VERSION ""

NS_ :

BS_:

BU_:
VAL_TABLE_ ETC_subModes 4 "Position Control" 3 "PWM Control" 2 "Calibration" 1 "Normal" 0 "Disabled" ;
VAL_TABLE_ ETC_modes 3 "Diagnostic" 2 "Run" 1 "Standby" 0 "ESTOP" ;
VAL_TABLE_ motorControlModes 2 "Position" 1 "PWM" 0 "Off" ;
VAL_TABLE_ throttlePosInputModes 2 "VectorBox" 1 "CCP" 0 "Disabled" ;

BO_ 3221225472 VECTOR__INDEPENDENT_SIG_MSG: 0 Vector__XXX
 SG_ ETC_motorDriverEnabled_Raw : 0|8@1+ (1,0) [0|255] "bool" Vector__XXX
 SG_ ETC_motorBPWM_Raw : 0|8@1+ (1,0) [0|255] "%" Vector__XXX
 SG_ ETC_motorAPWM_Raw : 0|8@1+ (1,0) [0|255] "%" Vector__XXX

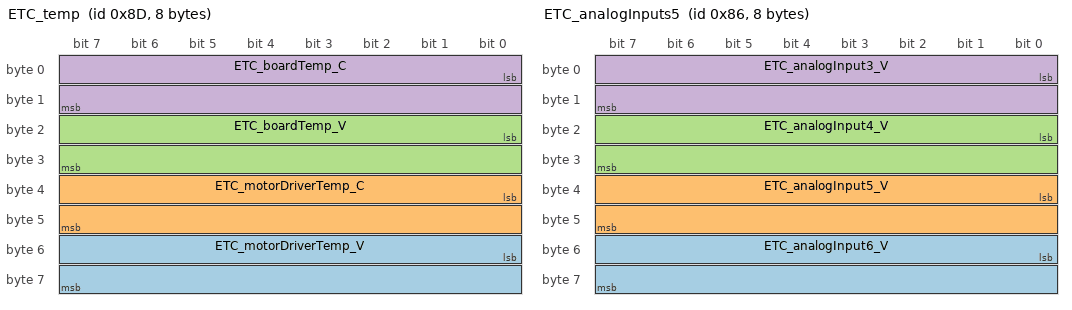
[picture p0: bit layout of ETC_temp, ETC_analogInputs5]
BO_ 141 ETC_temp: 8 Vector__XXX
 SG_ ETC_motorDriverTemp_V : 48|16@1+ (0.01,0) [0|655.35] "" Vector__XXX
 SG_ ETC_motorDriverTemp_C : 32|16@1- (0.01,0) [-327.68|327.67] "" Vector__XXX
 SG_ ETC_boardTemp_V : 16|16@1+ (0.01,0) [0|655.35] "" Vector__XXX
 SG_ ETC_boardTemp_C : 0|16@1- (0.01,0) [-327.68|327.67] "" Vector__XXX

BO_ 134 ETC_analogInputs5: 8 Vector__XXX
 SG_ ETC_analogInput6_V : 48|16@1+ (0.01,0) [0|655.35] "" Vector__XXX
 SG_ ETC_analogInput5_V : 32|16@1+ (0.01,0) [0|655.35] "" Vector__XXX
 SG_ ETC_analogInput4_V : 16|16@1+ (0.01,0) [0|655.35] "" Vector__XXX
 SG_ ETC_analogInput3_V : 0|16@1+ (0.01,0) [0|655.35] "" Vector__XXX

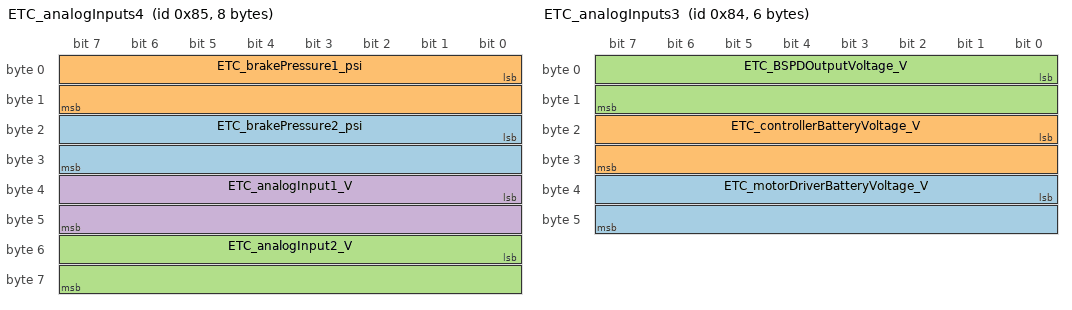
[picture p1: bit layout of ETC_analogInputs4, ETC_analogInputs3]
BO_ 133 ETC_analogInputs4: 8 Vector__XXX
 SG_ ETC_brakePressure2_psi : 16|16@1+ (0.01,0) [0|655.35] "" Vector__XXX
 SG_ ETC_brakePressure1_psi : 0|16@1+ (0.01,0) [0|655.35] "" Vector__XXX
 SG_ ETC_analogInput2_V : 48|16@1+ (0.01,0) [0|655.35] "" Vector__XXX
 SG_ ETC_analogInput1_V : 32|16@1+ (0.01,0) [0|655.35] "" Vector__XXX

BO_ 132 ETC_analogInputs3: 6 Vector__XXX
 SG_ ETC_motorDriverBatteryVoltage_V : 32|16@1- (0.001,0) [-32.768|32.767] "V" Vector__XXX
 SG_ ETC_controllerBatteryVoltage_V : 16|16@1- (0.001,0) [-32.768|32.767] "V" Vector__XXX
 SG_ ETC_BSPDOutputVoltage_V : 0|16@1- (0.001,0) [-32.768|32.767] "V" Vector__XXX

BO_ 140 ETC_adcRaw6: 4 Vector__XXX
 SG_ ETC_intlADC_A3_Raw : 16|16@1+ (1,0) [0|0] "cnt" Vector__XXX
 SG_ ETC_intlADC_A2_Raw : 0|16@1+ (1,0) [0|0] "cnt" Vector__XXX

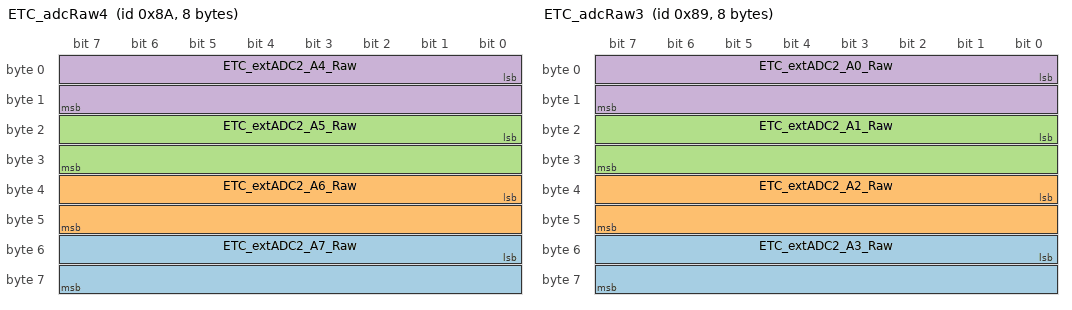
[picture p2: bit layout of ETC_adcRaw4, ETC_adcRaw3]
BO_ 138 ETC_adcRaw4: 8 Vector__XXX
 SG_ ETC_extADC2_A7_Raw : 48|16@1+ (1,0) [0|0] "cnt" Vector__XXX
 SG_ ETC_extADC2_A6_Raw : 32|16@1+ (1,0) [0|0] "cnt" Vector__XXX
 SG_ ETC_extADC2_A5_Raw : 16|16@1+ (1,0) [0|0] "cnt" Vector__XXX
 SG_ ETC_extADC2_A4_Raw : 0|16@1+ (1,0) [0|0] "cnt" Vector__XXX

BO_ 137 ETC_adcRaw3: 8 Vector__XXX
 SG_ ETC_extADC2_A3_Raw : 48|16@1+ (1,0) [0|0] "cnt" Vector__XXX
 SG_ ETC_extADC2_A2_Raw : 32|16@1+ (1,0) [0|0] "cnt" Vector__XXX
 SG_ ETC_extADC2_A1_Raw : 16|16@1+ (1,0) [0|0] "cnt" Vector__XXX
 SG_ ETC_extADC2_A0_Raw : 0|16@1+ (1,0) [0|0] "cnt" Vector__XXX

BO_ 1026 ETC_faultsRaw: 1 Vector__XXX
 SG_ ETC_lowBattVoltFaultRaw_bool : 1|1@1+ (1,0) [0|0] "" Vector__XXX
 SG_ ETC_subModeFaultRaw_bool : 0|1@1+ (1,0) [0|0] "" Vector__XXX

BO_ 1025 ETC_faults: 1 Vector__XXX
 SG_ ETC_lowBattVoltFault_bool : 1|1@1+ (1,0) [0|0] "" Vector__XXX
 SG_ ETC_subModeFault_bool : 0|1@1+ (1,0) [0|0] "" Vector__XXX

BO_ 1003 ETC_motorControlData2: 4 Vector__XXX
 SG_ ETC_motorCommand : 16|16@1- (1,0) [-32768|32767] "" Vector__XXX
 SG_ ETC_throttlePositionCmd : 0|16@1+ (0.01,0) [0|655.35] "%" Vector__XXX

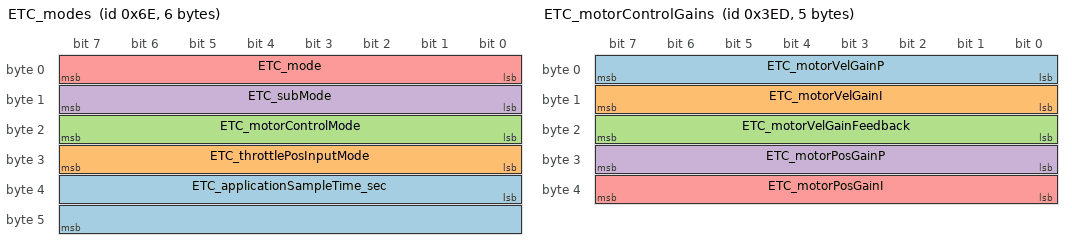
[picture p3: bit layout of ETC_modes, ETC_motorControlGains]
BO_ 110 ETC_modes: 6 Vector__XXX
 SG_ ETC_applicationSampleTime_sec : 32|16@1+ (1E-005,0) [0|0.65535] "" Vector__XXX
 SG_ ETC_throttlePosInputMode : 24|8@1+ (1,0) [0|255] "bool" Vector__XXX
 SG_ ETC_motorControlMode : 16|8@1+ (1,0) [0|255] "bool" Vector__XXX
 SG_ ETC_subMode : 8|8@1+ (1,0) [0|255] "" Vector__XXX
 SG_ ETC_mode : 0|8@1+ (1,0) [0|255] "" Vector__XXX

BO_ 1005 ETC_motorControlGains: 5 Vector__XXX
 SG_ ETC_motorVelGainP : 0|8@1+ (0.1,0) [0|25.5] "" Vector__XXX
 SG_ ETC_motorVelGainI : 8|8@1+ (0.1,0) [0|25.5] "" Vector__XXX
 SG_ ETC_motorVelGainFeedback : 16|8@1+ (0.1,0) [0|25.5] "" Vector__XXX
 SG_ ETC_motorPosGainP : 24|8@1+ (0.1,0) [0|25.5] "" Vector__XXX
 SG_ ETC_motorPosGainI : 32|8@1+ (0.1,0) [0|25.5] "" Vector__XXX

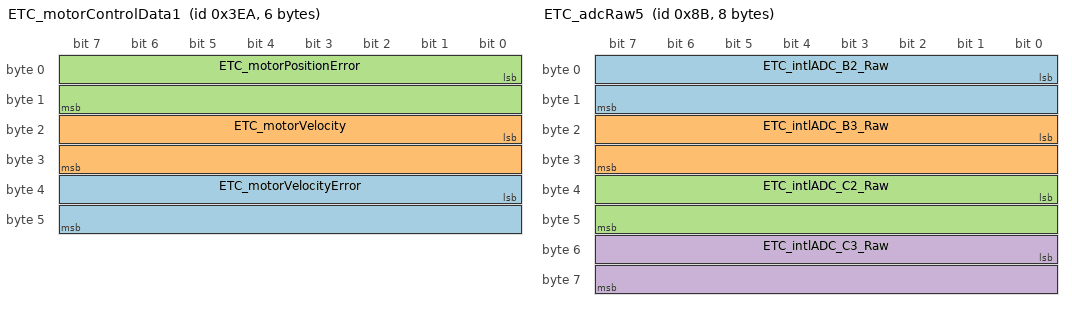
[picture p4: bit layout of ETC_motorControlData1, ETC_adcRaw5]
BO_ 1002 ETC_motorControlData1: 6 Vector__XXX
 SG_ ETC_motorVelocityError : 32|16@1- (0.01,0) [-327.68|327.67] "" Vector__XXX
 SG_ ETC_motorVelocity : 16|16@1- (0.01,0) [-327.68|327.67] "" Vector__XXX
 SG_ ETC_motorPositionError : 0|16@1- (0.01,0) [-327.68|327.67] "" Vector__XXX

BO_ 139 ETC_adcRaw5: 8 Vector__XXX
 SG_ ETC_intlADC_B2_Raw : 0|16@1+ (1,0) [0|0] "cnt" Vector__XXX
 SG_ ETC_intlADC_B3_Raw : 16|16@1+ (1,0) [0|0] "cnt" Vector__XXX
 SG_ ETC_intlADC_C2_Raw : 32|16@1+ (1,0) [0|0] "cnt" Vector__XXX
 SG_ ETC_intlADC_C3_Raw : 48|16@1+ (1,0) [0|0] "cnt" Vector__XXX

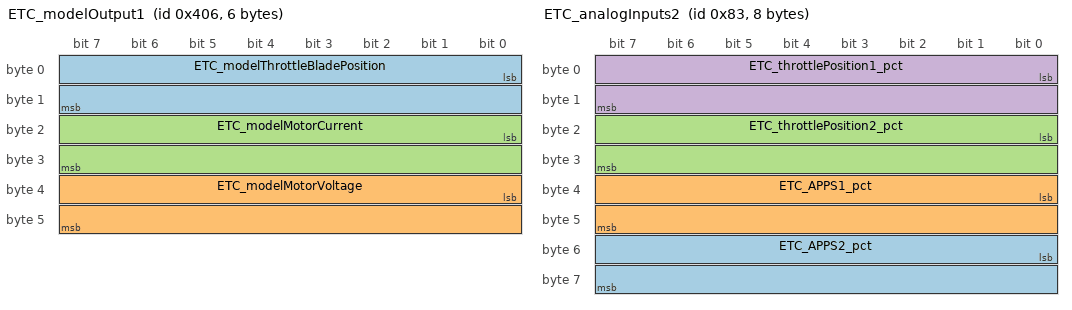
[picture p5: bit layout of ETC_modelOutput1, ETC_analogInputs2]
BO_ 1030 ETC_modelOutput1: 6 Vector__XXX
 SG_ ETC_modelThrottleBladePosition : 0|16@1+ (0.01,0) [0|655.35] "pct" Vector__XXX
 SG_ ETC_modelMotorVoltage : 32|16@1- (0.001,0) [-32.768|32.767] "V" Vector__XXX
 SG_ ETC_modelMotorCurrent : 16|16@1- (0.001,0) [-32.768|32.767] "A" Vector__XXX

BO_ 131 ETC_analogInputs2: 8 Vector__XXX
 SG_ ETC_APPS2_pct : 48|16@1+ (0.01,0) [0|655.35] "" Vector__XXX
 SG_ ETC_APPS1_pct : 32|16@1+ (0.01,0) [0|655.35] "" Vector__XXX
 SG_ ETC_throttlePosition2_pct : 16|16@1+ (0.01,0) [0|655.35] "" Vector__XXX
 SG_ ETC_throttlePosition1_pct : 0|16@1+ (0.01,0) [0|655.35] "" Vector__XXX

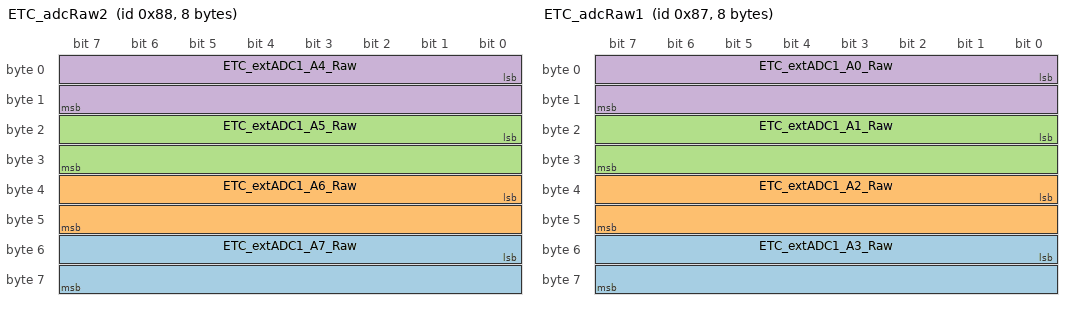
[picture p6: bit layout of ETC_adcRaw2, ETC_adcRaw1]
BO_ 136 ETC_adcRaw2: 8 Vector__XXX
 SG_ ETC_extADC1_A7_Raw : 48|16@1+ (1,0) [0|0] "cnt" Vector__XXX
 SG_ ETC_extADC1_A6_Raw : 32|16@1+ (1,0) [0|0] "cnt" Vector__XXX
 SG_ ETC_extADC1_A5_Raw : 16|16@1+ (1,0) [0|0] "cnt" Vector__XXX
 SG_ ETC_extADC1_A4_Raw : 0|16@1+ (1,0) [0|0] "cnt" Vector__XXX

BO_ 135 ETC_adcRaw1: 8 Vector__XXX
 SG_ ETC_extADC1_A3_Raw : 48|16@1+ (1,0) [0|0] "cnt" Vector__XXX
 SG_ ETC_extADC1_A2_Raw : 32|16@1+ (1,0) [0|0] "cnt" Vector__XXX
 SG_ ETC_extADC1_A1_Raw : 16|16@1+ (1,0) [0|0] "cnt" Vector__XXX
 SG_ ETC_extADC1_A0_Raw : 0|16@1+ (1,0) [0|0] "cnt" Vector__XXX

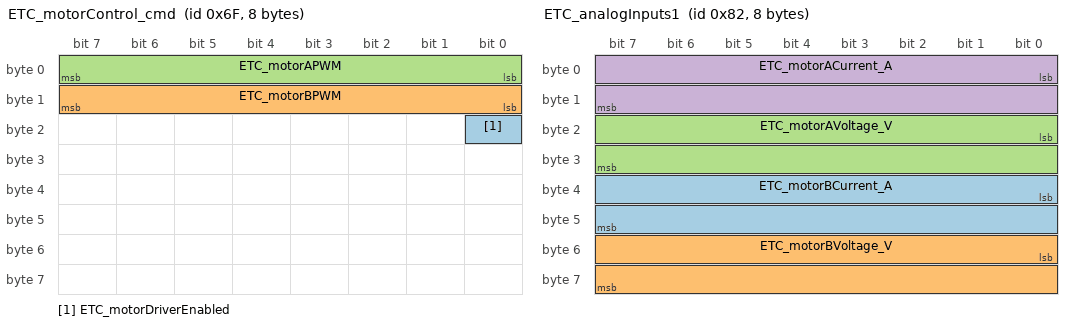
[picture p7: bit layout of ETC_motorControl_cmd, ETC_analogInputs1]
BO_ 111 ETC_motorControl_cmd: 8 Vector__XXX
 SG_ ETC_motorDriverEnabled : 16|1@1+ (1,0) [0|1] "bool" Vector__XXX
 SG_ ETC_motorBPWM : 8|8@1+ (1,0) [0|255] "%" Vector__XXX
 SG_ ETC_motorAPWM : 0|8@1+ (1,0) [0|255] "%" Vector__XXX

BO_ 130 ETC_analogInputs1: 8 Vector__XXX
 SG_ ETC_motorBCurrent_A : 32|16@1- (0.001,0) [-32.768|32.767] "A" Vector__XXX
 SG_ ETC_motorBVoltage_V : 48|16@1- (0.001,0) [-32.768|32.767] "V" Vector__XXX
 SG_ ETC_motorAVoltage_V : 16|16@1- (0.001,0) [-32.768|32.767] "V" Vector__XXX
 SG_ ETC_motorACurrent_A : 0|16@1- (0.001,0) [-32.768|32.767] "A" Vector__XXX

CM_ BO_ 3221225472 "This is a message for not used signals, created by Vector CANdb++ DBC OLE DB Provider.";
VAL_ 110 ETC_throttlePosInputMode 2 "VectorBox" 1 "CCP" 0 "Disabled" ;
VAL_ 110 ETC_motorControlMode 2 "Position" 1 "PWM" 0 "Off" ;
VAL_ 110 ETC_subMode 4 "Position Control" 3 "PWM Control" 2 "Calibration" 1 "Normal" 0 "Disabled" ;
VAL_ 110 ETC_mode 3 "Diagnostic" 2 "Run" 1 "Standby" 0 "ESTOP" ;
